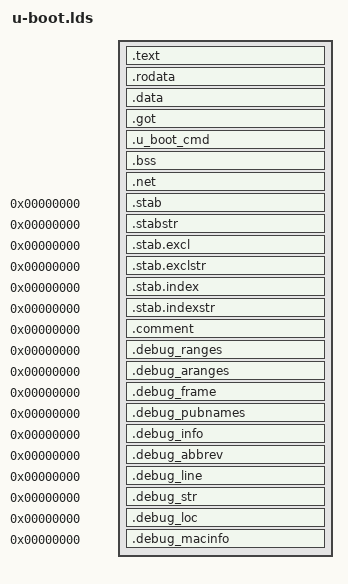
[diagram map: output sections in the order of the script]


OUTPUT_FORMAT("elf32-littlearc", "elf32-littlearc", "elf32-littlearc")
OUTPUT_ARCH(arc)
ENTRY(_start)
SECTIONS
{
	. = 0x00000000;

	. = ALIGN(4);
	.text	:
	{
		*arch/arm/cpu/aml_meson/start.o	(.text)
		*(.text)
	}

	. = ALIGN(4);
	.rodata : { *(SORT_BY_ALIGNMENT(SORT_BY_NAME(.rodata*))) }

	. = ALIGN(4);
	.data : { *(.data) }

	. = ALIGN(4);
	.got : { *(.got) }

	__u_boot_cmd_start = .;
	.u_boot_cmd : { *(.u_boot_cmd) }
	__u_boot_cmd_end = .;

	. = ALIGN(4);
	__bss_start = .;
	.bss : { *(.bss) }
	
	.net ALIGN(0x2000):
	{
		__net_dma_start	=	.;
		. = __net_dma_start + 0x20000;
		__net_dma_end = .;
	}
	__bss_end = .;
	_end = .;
	
	
	/* Stabs debugging sections.	*/
	.stab 0 : { *(.stab) }
	.stabstr 0 : { *(.stabstr) }
	.stab.excl 0 : { *(.stab.excl) }
	.stab.exclstr 0 : { *(.stab.exclstr) }
	.stab.index 0 : { *(.stab.index) }
	.stab.indexstr 0 : { *(.stab.indexstr) }
	.comment 0 : { *(.comment) }
	.debug_ranges 0 : { *(.debug_ranges) }
	.debug_aranges 0 : { *(.debug_aranges) }
	.debug_frame  0: { *(.debug_frame) }
	.debug_pubnames 0 : { *(.debug_pubnames) }
	.debug_info 0 : { *(.debug_info) }
	.debug_abbrev 0 : { *(.debug_abbrev) }
	.debug_line 0 : { *(.debug_line) }
	.debug_str 0 : { *(.debug_str) }
	.debug_loc 0 : { *(.debug_loc) }
	.debug_macinfo 0 : { *(.debug_macinfo) }
	
	
}
